# Ctrl register map
File version: 1.0
Register map Ctrl
Registers are 32-bit, read-write, no defined reset value unless marked. A register's access mark holds for its fields unless they carry their own. Offsets are from the block's base; lines under a group give offsets from that group; [hi:lo] are bit positions; {n}, {i} and the like mark numbered series; 'fields as' and 'values as' point back to an identical list; <NAME> marks a mode.

## Memory map
0x00000000 Ctrl size 0x1C — Ctrl (soc)

## Ctrl — Ctrl (soc)
Base 0x00000000
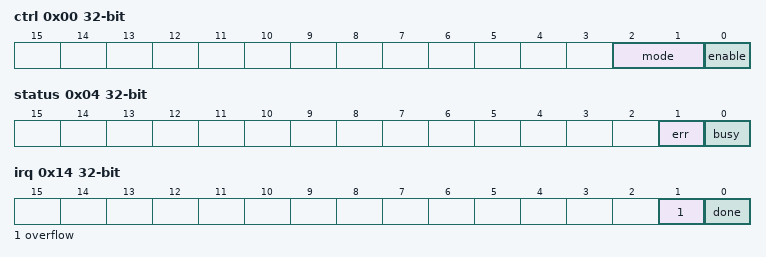
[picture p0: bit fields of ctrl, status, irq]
0x00 ctrl — Engine control.
  [2:1] mode
    0=Off; 1=Slow; 2=Fast; 3=Turbo
  [0] enable
0x04 status ro
  [1] err, [0] busy
0x08 count — Bytes processed <since reset> & so on.
0x10 fifo 8-bit wo
0x14 irq write-1-clears
  [1] overflow write-1-clears, [0] done write-1-clears
0x18 irq_set write-1-sets
